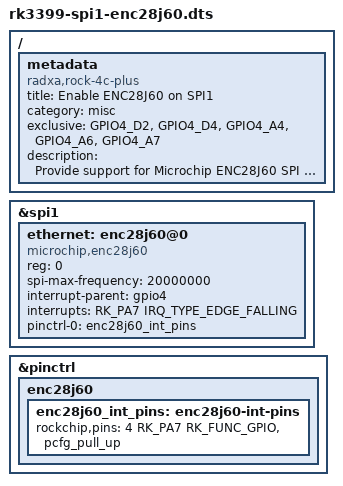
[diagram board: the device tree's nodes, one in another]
/dts-v1/;
/plugin/;

#include <dt-bindings/gpio/gpio.h>
#include <dt-bindings/pinctrl/rockchip.h>
#include <dt-bindings/interrupt-controller/irq.h>

/ {
	metadata {
		title = "Enable ENC28J60 on SPI1";
		compatible = "radxa,rock-4c-plus";
		category = "misc";
		exclusive = "GPIO4_D2", "GPIO4_D4", "GPIO4_A4", "GPIO4_A6", "GPIO4_A7";
		description = "Provide support for Microchip ENC28J60 SPI Ethernet controller on GPIO pins.\nPin definition:\nMOSI=19 MISO=21 SCK=23 CS=24 INT=40";
	};

	fragment@0 {
		target = <&spi1>;
		__overlay__ {
			#address-cells = <1>;
			#size-cells = <0>;
			status = "okay";

			ethernet: enc28j60@0 {
				compatible = "microchip,enc28j60";
				reg = <0>;
				spi-max-frequency = <20000000>;
				interrupt-parent = <&gpio4>;
				interrupts = <RK_PA7 IRQ_TYPE_EDGE_FALLING>;
				pinctrl-names = "default";
				pinctrl-0 = <&enc28j60_int_pins>;
			};
		};
	};

	fragment@1 {
		target = <&pinctrl>;
		__overlay__ {
			enc28j60 {
				enc28j60_int_pins: enc28j60-int-pins {
					rockchip,pins = <4 RK_PA7 RK_FUNC_GPIO &pcfg_pull_up>;
				};
			};
		};
	};
};
